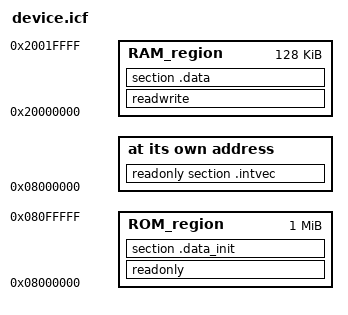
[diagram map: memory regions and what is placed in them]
//
//  IAR Linker Script for the STM32F207ZG
//

define symbol __intvec_start__ = 0x08000000;
define symbol __ROM_start__    = 0x08000000;
define symbol __ROM_end__      = 0x080FFFFF;
define symbol __RAM_start__    = 0x20000000;
define symbol __RAM_end__      = 0x2001FFFF;
define symbol __stack_size__   = 0x2000;
define symbol __heap_size__    = 0x2000;

define memory mem with size = 4G;
define region ROM_region    = mem:[from __ROM_start__   to __ROM_end__];
define region RAM_region    = mem:[from __RAM_start__   to __RAM_end__];

do not initialize  { section .noinit };
initialize manually { section .data };

place at address mem:__intvec_start__ { readonly section .intvec };

place in ROM_region { readonly, section .data_init };
place in RAM_region { readwrite, section .data };

define symbol __stack = __RAM_start__ + 128k;
export symbol __stack;
